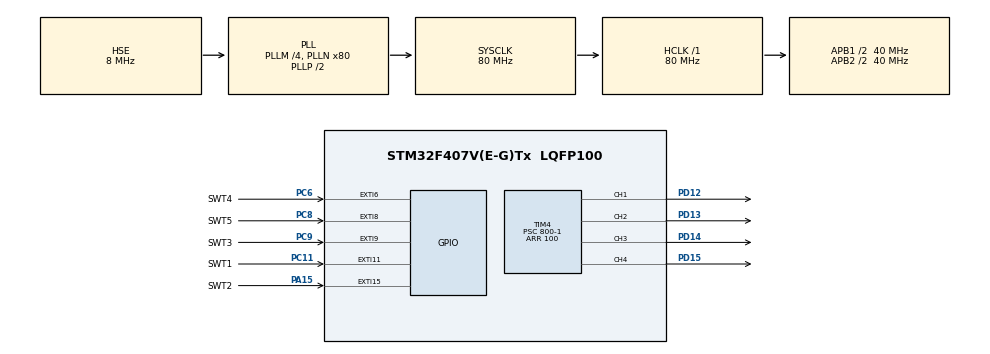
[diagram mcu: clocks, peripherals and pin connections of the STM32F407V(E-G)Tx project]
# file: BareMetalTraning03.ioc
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Mcu.Family=STM32F4
Mcu.Name=STM32F407V(E-G)Tx
Mcu.Package=LQFP100
NVIC.EXTI15_10_IRQn=true\:0\:0\:false\:false\:true\:true\:true\:true
NVIC.EXTI9_5_IRQn=true\:0\:0\:false\:false\:true\:true\:true\:true
NVIC.PriorityGroup=NVIC_PRIORITYGROUP_4
PA13.Mode=Serial_Wire
PA13.Signal=SYS_JTMS-SWDIO
PA14.Mode=Serial_Wire
PA14.Signal=SYS_JTCK-SWCLK
PA15.GPIO_Label=SWT2
PA15.GPIO_ModeDefaultEXTI=GPIO_MODE_IT_FALLING
PA15.GPIO_PuPd=GPIO_PULLUP
PA15.Signal=GPXTI15
PC11.GPIO_Label=SWT1
PC11.GPIO_ModeDefaultEXTI=GPIO_MODE_IT_FALLING
PC11.GPIO_PuPd=GPIO_PULLUP
PC11.Signal=GPXTI11
PC6.GPIO_Label=SWT4
PC6.GPIO_ModeDefaultEXTI=GPIO_MODE_IT_FALLING
PC6.GPIO_PuPd=GPIO_PULLUP
PC6.Signal=GPXTI6
PC8.GPIO_Label=SWT5
PC8.GPIO_ModeDefaultEXTI=GPIO_MODE_IT_FALLING
PC8.GPIO_PuPd=GPIO_PULLUP
PC8.Signal=GPXTI8
PC9.GPIO_Label=SWT3
PC9.GPIO_ModeDefaultEXTI=GPIO_MODE_IT_FALLING
PC9.GPIO_PuPd=GPIO_PULLUP
PC9.Signal=GPXTI9
PD12.Signal=S_TIM4_CH1
PD13.Signal=S_TIM4_CH2
PD14.Signal=S_TIM4_CH3
PD15.Signal=S_TIM4_CH4
PH0-OSC_IN.Mode=HSE-External-Oscillator
PH0-OSC_IN.Signal=RCC_OSC_IN
PH1-OSC_OUT.Mode=HSE-External-Oscillator
PH1-OSC_OUT.Signal=RCC_OSC_OUT
ProjectManager.HeapSize=0x200
ProjectManager.StackSize=0x400
ProjectManager.TargetToolchain=STM32CubeIDE
RCC.48MHZClocksFreq_Value=40000000
RCC.AHBFreq_Value=80000000
RCC.APB1CLKDivider=RCC_HCLK_DIV2
RCC.APB1Freq_Value=40000000
RCC.APB1TimFreq_Value=80000000
RCC.APB2CLKDivider=RCC_HCLK_DIV2
RCC.APB2Freq_Value=40000000
RCC.APB2TimFreq_Value=80000000
RCC.CortexFreq_Value=80000000
RCC.EnbaleCSS=true
RCC.HCLKFreq_Value=80000000
RCC.HSE_VALUE=8000000
RCC.HSI_VALUE=16000000
RCC.LSE_VALUE=32768
RCC.PLLM=4
RCC.PLLN=80
RCC.PLLSourceVirtual=RCC_PLLSOURCE_HSE
RCC.SYSCLKFreq_VALUE=80000000
RCC.SYSCLKSource=RCC_SYSCLKSOURCE_PLLCLK
RCC.VCOOutputFreq_Value=160000000
SH.S_TIM4_CH1.0=TIM4_CH1,PWM Generation1 CH1
SH.S_TIM4_CH2.0=TIM4_CH2,PWM Generation2 CH2
SH.S_TIM4_CH3.0=TIM4_CH3,PWM Generation3 CH3
SH.S_TIM4_CH4.0=TIM4_CH4,PWM Generation4 CH4
TIM4.Channel-PWM\ Generation1\ CH1=TIM_CHANNEL_1
TIM4.Channel-PWM\ Generation2\ CH2=TIM_CHANNEL_2
TIM4.Channel-PWM\ Generation3\ CH3=TIM_CHANNEL_3
TIM4.Channel-PWM\ Generation4\ CH4=TIM_CHANNEL_4
TIM4.OCPolarity_1=TIM_OCPOLARITY_HIGH
TIM4.Period=100
TIM4.Prescaler=800-1
TIM4.Pulse-PWM\ Generation1\ CH1=0
TIM4.Pulse-PWM\ Generation2\ CH2=0
TIM4.Pulse-PWM\ Generation3\ CH3=0
VP_TIM4_VS_ClockSourceINT.Mode=Internal
board=custom

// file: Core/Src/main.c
/* USER CODE BEGIN Header */
/* USER CODE END Header */
#include "main.h"
#include "tim.h"
#include "gpio.h"

/* USER CODE BEGIN Includes */
#include "TIM4_PWM.h"

/* USER CODE END Includes */

/* USER CODE BEGIN PV */
#define DEBOUNCE 50 // button debounce timing
uint32_t last_time = 0;
/* USER CODE END PV */

void SystemClock_Config(void);
/* USER CODE BEGIN PFP */
void HAL_GPIO_EXTI_Callback(uint16_t GPIO_Pin)
{
	uint32_t time = HAL_GetTick();

		if (time - last_time > DEBOUNCE)
		{
	_Button_reader(GPIO_Pin);
	_Tim_second_init();
		}
		last_time = time;

}
/* USER CODE END PFP */

int main(void)
{

  /* MCU Configuration--------------------------------------------------------*/

  /* Reset of all peripherals, Initializes the Flash interface and the Systick. */
  HAL_Init();

  /* Configure the system clock */
  SystemClock_Config();

  /* Initialize all configured peripherals */
  MX_GPIO_Init();
  MX_TIM4_Init();
  _Tim_imit();
  /* USER CODE BEGIN 2 */

  //_Tim_imit();
  while(1){

  };
  /* USER CODE END 2 */

  /* Infinite loop */

}

void SystemClock_Config(void)
{
  RCC_OscInitTypeDef RCC_OscInitStruct = {0};
  RCC_ClkInitTypeDef RCC_ClkInitStruct = {0};

  /** Configure the main internal regulator output voltage
  */
  __HAL_RCC_PWR_CLK_ENABLE();
  __HAL_PWR_VOLTAGESCALING_CONFIG(PWR_REGULATOR_VOLTAGE_SCALE1);

  /** Initializes the RCC Oscillators according to the specified parameters
  * in the RCC_OscInitTypeDef structure.
  */
  RCC_OscInitStruct.OscillatorType = RCC_OSCILLATORTYPE_HSE;
  RCC_OscInitStruct.HSEState = RCC_HSE_ON;
  RCC_OscInitStruct.PLL.PLLState = RCC_PLL_ON;
  RCC_OscInitStruct.PLL.PLLSource = RCC_PLLSOURCE_HSE;
  RCC_OscInitStruct.PLL.PLLM = 4;
  RCC_OscInitStruct.PLL.PLLN = 80;
  RCC_OscInitStruct.PLL.PLLP = RCC_PLLP_DIV2;
  RCC_OscInitStruct.PLL.PLLQ = 4;
  if (HAL_RCC_OscConfig(&RCC_OscInitStruct) != HAL_OK)
  {
    Error_Handler();
  }

  /** Initializes the CPU, AHB and APB buses clocks
  */
  RCC_ClkInitStruct.ClockType = RCC_CLOCKTYPE_HCLK|RCC_CLOCKTYPE_SYSCLK
                              |RCC_CLOCKTYPE_PCLK1|RCC_CLOCKTYPE_PCLK2;
  RCC_ClkInitStruct.SYSCLKSource = RCC_SYSCLKSOURCE_PLLCLK;
  RCC_ClkInitStruct.AHBCLKDivider = RCC_SYSCLK_DIV1;
  RCC_ClkInitStruct.APB1CLKDivider = RCC_HCLK_DIV2;
  RCC_ClkInitStruct.APB2CLKDivider = RCC_HCLK_DIV2;

  if (HAL_RCC_ClockConfig(&RCC_ClkInitStruct, FLASH_LATENCY_2) != HAL_OK)
  {
    Error_Handler();
  }

  /** Enables the Clock Security System
  */
  HAL_RCC_EnableCSS();
}

void Error_Handler(void)
{
}
